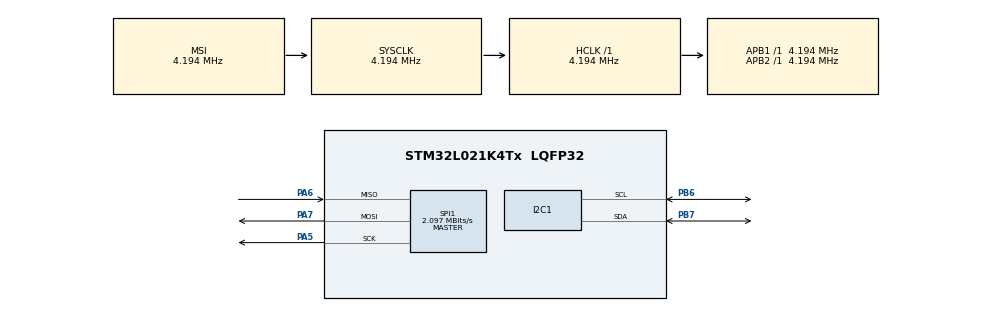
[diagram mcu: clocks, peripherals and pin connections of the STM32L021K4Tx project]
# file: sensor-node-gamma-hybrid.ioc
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I2C1.Timing=0x00100E16
Mcu.Family=STM32L0
Mcu.Name=STM32L021K4Tx
Mcu.Package=LQFP32
PA13.Mode=Serial_Wire
PA13.Signal=SYS_SWDIO
PA14.Mode=Serial_Wire
PA14.Signal=SYS_SWCLK
PA5.Mode=Full_Duplex_Master
PA5.Signal=SPI1_SCK
PA6.Mode=Full_Duplex_Master
PA6.Signal=SPI1_MISO
PA7.Mode=Full_Duplex_Master
PA7.Signal=SPI1_MOSI
PB6.Mode=I2C
PB6.Signal=I2C1_SCL
PB7.Mode=I2C
PB7.Signal=I2C1_SDA
ProjectManager.HeapSize=0x200
ProjectManager.StackSize=0x400
ProjectManager.TargetToolchain=Makefile
RCC.AHBFreq_Value=4194000
RCC.APB1Freq_Value=4194000
RCC.APB1TimFreq_Value=4194000
RCC.APB2Freq_Value=4194000
RCC.APB2TimFreq_Value=4194000
RCC.HCLKFreq_Value=4194000
RCC.HSE_VALUE=8000000
RCC.HSI16_VALUE=16000000
RCC.HSI_VALUE=16000000
RCC.LSE_VALUE=32768
RCC.MSIClockRange=RCC_MSIRANGE_6
RCC.MSI_VALUE=4194000
RCC.SYSCLKFreq_VALUE=4194000
RCC.VCOOutputFreq_Value=48000000
SPI1.CalculateBaudRate=2.097 MBits/s
SPI1.Direction=SPI_DIRECTION_2LINES
SPI1.Mode=SPI_MODE_MASTER
SPI1.VirtualType=VM_MASTER
board=custom

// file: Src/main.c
/* USER CODE BEGIN Header */
/**
  ******************************************************************************
  * @file           : main.c
  * @brief          : Main program body
  ******************************************************************************
  ** This notice applies to any and all portions of this file
  * that are not between comment pairs USER CODE BEGIN and
  * USER CODE END. Other portions of this file, whether
  * inserted by the user or by software development tools
  * are owned by their respective copyright owners.
  *
  * COPYRIGHT(c) 2018 STMicroelectronics
  *
  * Redistribution and use in source and binary forms, with or without modification,
  * are permitted provided that the following conditions are met:
  *   1. Redistributions of source code must retain the above copyright notice,
  *      this list of conditions and the following disclaimer.
  *   2. Redistributions in binary form must reproduce the above copyright notice,
  *      this list of conditions and the following disclaimer in the documentation
  *      and/or other materials provided with the distribution.
  *   3. Neither the name of STMicroelectronics nor the names of its contributors
  *      may be used to endorse or promote products derived from this software
  *      without specific prior written permission.
  *
  * THIS SOFTWARE IS PROVIDED BY THE COPYRIGHT HOLDERS AND CONTRIBUTORS "AS IS"
  * AND ANY EXPRESS OR IMPLIED WARRANTIES, INCLUDING, BUT NOT LIMITED TO, THE
  * IMPLIED WARRANTIES OF MERCHANTABILITY AND FITNESS FOR A PARTICULAR PURPOSE ARE
  * DISCLAIMED. IN NO EVENT SHALL THE COPYRIGHT HOLDER OR CONTRIBUTORS BE LIABLE
  * FOR ANY DIRECT, INDIRECT, INCIDENTAL, SPECIAL, EXEMPLARY, OR CONSEQUENTIAL
  * DAMAGES (INCLUDING, BUT NOT LIMITED TO, PROCUREMENT OF SUBSTITUTE GOODS OR
  * SERVICES; LOSS OF USE, DATA, OR PROFITS; OR BUSINESS INTERRUPTION) HOWEVER
  * CAUSED AND ON ANY THEORY OF LIABILITY, WHETHER IN CONTRACT, STRICT LIABILITY,
  * OR TORT (INCLUDING NEGLIGENCE OR OTHERWISE) ARISING IN ANY WAY OUT OF THE USE
  * OF THIS SOFTWARE, EVEN IF ADVISED OF THE POSSIBILITY OF SUCH DAMAGE.
  *
  ******************************************************************************
  */
/* USER CODE END Header */

#include "main.h"
#include "i2c.h"
#include "spi.h"
#include "gpio.h"

void SystemClock_Config(void);

int main(void)
{

  /* MCU Configuration--------------------------------------------------------*/

  /* Reset of all peripherals, Initializes the Flash interface and the Systick. */
  HAL_Init();

  /* Configure the system clock */
  SystemClock_Config();

  /* Initialize all configured peripherals */
  MX_GPIO_Init();
  MX_SPI1_Init();
  MX_I2C1_Init();

  /* Infinite loop */
  /* USER CODE BEGIN WHILE */
  while (1)
  {
    uint8_t i2c_address = (0x70 << 1);
    volatile HAL_StatusTypeDef hal_status = HAL_I2C_IsDeviceReady(&hi2c1, i2c_address, 10, 1000);
    uint8_t com_wakeup[] = {0x35, 0x17};
    hal_status = HAL_I2C_Master_Transmit(&hi2c1, i2c_address, com_wakeup, 2, 1000);
    uint8_t com_meas[] = {0x7C, 0xA2};
    hal_status = HAL_I2C_Master_Transmit(&hi2c1, i2c_address, com_meas, 2, 1000);
    uint8_t raw_data[6];
    hal_status = HAL_I2C_Master_Receive(&hi2c1, i2c_address, raw_data, 6, 1000);

    volatile uint16_t raw_temp = (raw_data[0] << 8) + raw_data[1];
    volatile uint16_t raw_hum = (raw_data[3] << 8) + raw_data[4];

    volatile float temp = (float)raw_temp / (1 << 16) * 175 - 45;
    volatile float hum = (float)raw_hum / (1 << 16) * 100;

    // LL_I2C_EnableClockStretching(&hi2c1);
    // LL_I2C_Enable(&hi2c1);

    // write 0x3517
    // LL_I2C_HandleTransfer(&hi2c1, (0x70 << 1), LL_I2C_ADDRSLAVE_7BIT, 2, LL_I2C_MODE_AUTOEND, LL_I2C_GENERATE_START_WRITE);
    // while (LL_I2C_IsActiveFlag_TXE(&hi2c1) == 0) {}
    // LL_I2C_TransmitData8(&hi2c1, 0x35);
    // LL_I2C_TransmitData8(&hi2c1, 0x17);
    // // write 0x7CA2
    // LL_I2C_HandleTransfer(&hi2c1, (0x70 << 1), LL_I2C_ADDRSLAVE_7BIT, 2, LL_I2C_MODE_AUTOEND, LL_I2C_GENERATE_START_WRITE);
    // while (LL_I2C_IsActiveFlag_TXIS(&hi2c1) == 0) {}
    // LL_I2C_TransmitData8(&hi2c1, 0x7C);
    // LL_I2C_TransmitData8(&hi2c1, 0xA2);
    // // read 6 bytes
    // volatile uint16_t raw_temp;
    // volatile uint16_t raw_hum;
    // uint8_t crc_temp;
    // uint8_t crc_hum;
    // LL_I2C_HandleTransfer(&hi2c1, (0x70 << 1), LL_I2C_ADDRSLAVE_7BIT, 6, LL_I2C_MODE_AUTOEND, LL_I2C_GENERATE_START_READ);
    // while (LL_I2C_IsActiveFlag_RXNE(&hi2c1) == 0) {}
    // raw_temp = (LL_I2C_ReceiveData8(&hi2c1) << 8);
    // raw_temp += LL_I2C_ReceiveData8(&hi2c1);
    // crc_temp = LL_I2C_ReceiveData8(&hi2c1);
    // raw_hum = (LL_I2C_ReceiveData8(&hi2c1) << 8);
    // raw_hum += LL_I2C_ReceiveData8(&hi2c1);
    // crc_hum = LL_I2C_ReceiveData8(&hi2c1);

    // volatile float temp = ((float)raw_temp) / (2 << 16) * 175 - 45;
    // volatile float hum = ((float)raw_hum) / (2 << 16) * 100;

    volatile int tmp = 6;

    /* USER CODE END WHILE */

  }
}

void SystemClock_Config(void)
{
  RCC_OscInitTypeDef RCC_OscInitStruct = {0};
  RCC_ClkInitTypeDef RCC_ClkInitStruct = {0};
  RCC_PeriphCLKInitTypeDef PeriphClkInit = {0};

  /**Configure the main internal regulator output voltage
  */
  __HAL_PWR_VOLTAGESCALING_CONFIG(PWR_REGULATOR_VOLTAGE_SCALE1);
  /**Initializes the CPU, AHB and APB busses clocks
  */
  RCC_OscInitStruct.OscillatorType = RCC_OSCILLATORTYPE_MSI;
  RCC_OscInitStruct.MSIState = RCC_MSI_ON;
  RCC_OscInitStruct.MSICalibrationValue = 0;
  RCC_OscInitStruct.MSIClockRange = RCC_MSIRANGE_6;
  RCC_OscInitStruct.PLL.PLLState = RCC_PLL_NONE;
  if (HAL_RCC_OscConfig(&RCC_OscInitStruct) != HAL_OK)
  {
    Error_Handler();
  }
  /**Initializes the CPU, AHB and APB busses clocks
  */
  RCC_ClkInitStruct.ClockType = RCC_CLOCKTYPE_HCLK|RCC_CLOCKTYPE_SYSCLK
                              |RCC_CLOCKTYPE_PCLK1|RCC_CLOCKTYPE_PCLK2;
  RCC_ClkInitStruct.SYSCLKSource = RCC_SYSCLKSOURCE_MSI;
  RCC_ClkInitStruct.AHBCLKDivider = RCC_SYSCLK_DIV1;
  RCC_ClkInitStruct.APB1CLKDivider = RCC_HCLK_DIV1;
  RCC_ClkInitStruct.APB2CLKDivider = RCC_HCLK_DIV1;

  if (HAL_RCC_ClockConfig(&RCC_ClkInitStruct, FLASH_LATENCY_0) != HAL_OK)
  {
    Error_Handler();
  }
  PeriphClkInit.PeriphClockSelection = RCC_PERIPHCLK_I2C1;
  PeriphClkInit.I2c1ClockSelection = RCC_I2C1CLKSOURCE_PCLK1;
  if (HAL_RCCEx_PeriphCLKConfig(&PeriphClkInit) != HAL_OK)
  {
    Error_Handler();
  }
}

void Error_Handler(void)
{
}

/************************ (C) COPYRIGHT STMicroelectronics *****END OF FILE****/
